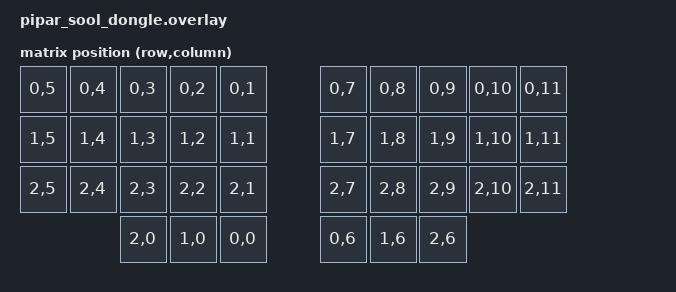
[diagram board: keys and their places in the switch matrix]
/*
 * Copyright (c) 2024 The ZMK Contributors
 *
 * SPDX-License-Identifier: MIT
 */
#include <dt-bindings/zmk/matrix_transform.h>
#include "pipar_sool-layouts.dtsi"

&physical_layout0 {
    transform = <&default_transform>;
    // zmk,kscan = &mock_kscan;
};

/ {
    chosen {
        zmk,kscan = &mock_kscan;
        zmk,physical-layout = &physical_layout0;
        zephyr,display = &st7789v;
    };

    default_transform: keymap_transform_0 {
        compatible = "zmk,matrix-transform";
        columns = <12>;
        rows = <3>;
                                    
        map = <
            RC(0,5)  RC(0,4)  RC(0,3)  RC(0,2)  RC(0,1)  RC(0,7)  RC(0,8)   RC(0,9)  RC(0,10)  RC(0,11)
            RC(1,5)  RC(1,4)  RC(1,3)  RC(1,2)  RC(1,1)  RC(1,7)  RC(1,8)   RC(1,9)  RC(1,10)  RC(1,11) 
            RC(2,5)  RC(2,4)  RC(2,3)  RC(2,2)  RC(2,1)  RC(2,7)  RC(2,8)   RC(2,9)  RC(2,10)  RC(2,11) 
                              RC(2,0)  RC(1,0)  RC(0,0)  RC(0,6)  RC(1,6)   RC(2,6)
        >;
        
    };
    mock_kscan: kscan0 {
        compatible = "zmk,kscan-mock";
        columns = <0>;
        rows = <0>;
        events = <0>;
    };

    pwmleds {
        compatible = "pwm-leds";
        disp_bl: pwm_led_1 {
            pwms = <&pwm1 0 PWM_MSEC(1) PWM_POLARITY_NORMAL>;
        };
    };
    
};

&spi2 {
   status = "disabled";
};

&pinctrl {
   spi3_default: spi3_default {
		group1 {
			psels = <NRF_PSEL(SPIM_SCK, 0, 5)>,
				<NRF_PSEL(SPIM_MOSI, 0, 4)>,
				<NRF_PSEL(SPIM_MISO, 1, 10)>;
		};
	};

	spi3_sleep: spi3_sleep {
		group1 {
			psels = <NRF_PSEL(SPIM_SCK, 0, 5)>,
				<NRF_PSEL(SPIM_MOSI, 0, 4)>,
				<NRF_PSEL(SPIM_MISO, 1, 10)>;
			low-power-enable;
		};
	};

   pwm1_default: pwm1_default {
      group1 {
         psels = <NRF_PSEL(PWM_OUT0, 1, 11)>;
         nordic,invert;
      };
   };

   pwm1_sleep: pwm1_sleep {
      group1 {
         psels = <NRF_PSEL(PWM_OUT0, 1, 11)>;
         low-power-enable;
      };
   };
};

disp_spi: &spi3 {
   status = "okay";
   pinctrl-0 = <&spi3_default>;
	pinctrl-1 = <&spi3_sleep>;
	pinctrl-names = "default", "sleep";
//    cs-gpios = <&xiao_d 9 GPIO_ACTIVE_LOW>;

   st7789v: st7789v@0 {
       compatible = "sitronix,st7789v";
       spi-max-frequency = <31000000>;
       reg = <0>;
       cmd-data-gpios = <&xiao_d 7 GPIO_ACTIVE_LOW>;
       reset-gpios = <&xiao_d 3 GPIO_ACTIVE_LOW>;
       width = <240>;
       height = <240>;
       x-offset = <0>;
       y-offset = <20>;
       vcom = <0x19>;
       gctrl = <0x35>;
       vrhs = <0x12>;
       vdvs = <0x20>;
       mdac = <0x00>;
       gamma = <0x01>;
       colmod = <0x05>;
       lcm = <0x2c>;
       porch-param = [ 0c 0c 00 33 33  ];
       cmd2en-param = [ 5a 69 02 01  ];
       pwctrl1-param = [ a4 a1  ];
       pvgam-param = [ D0 04 0D 11 13 2B 3F 54 4C 18 0D 0B 1F 23  ];
       nvgam-param = [ D0 04 0C 11 13 2C 3F 44 51 2F 1F 1F 20 23  ];
       ram-param = [ 00 F0  ];
       rgb-param = [ CD 08 14  ];
   };
};

&pwm1 {
  status = "okay";
  pinctrl-0 = <&pwm1_default>;
  pinctrl-1 = <&pwm1_sleep>;
  pinctrl-names = "default", "sleep";
};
